# ECC_AGG_TOP_ECC_AGG_TOP register map
Vendor: Texas Instruments
Peripheral module from a debugger description file (folder AM263).
Registers are 8-bit, read-write, reset 0x0 unless marked. A register's access mark holds for its fields unless they carry their own. Offsets are as the file gives them; lines under a group give offsets from that group; [hi:lo] are bit positions; {n}, {i} and the like mark numbered series; 'fields as' and 'values as' point back to an identical list; <NAME> marks a mode.

## ECC_AGG_TOP_ECC_AGG_TOP
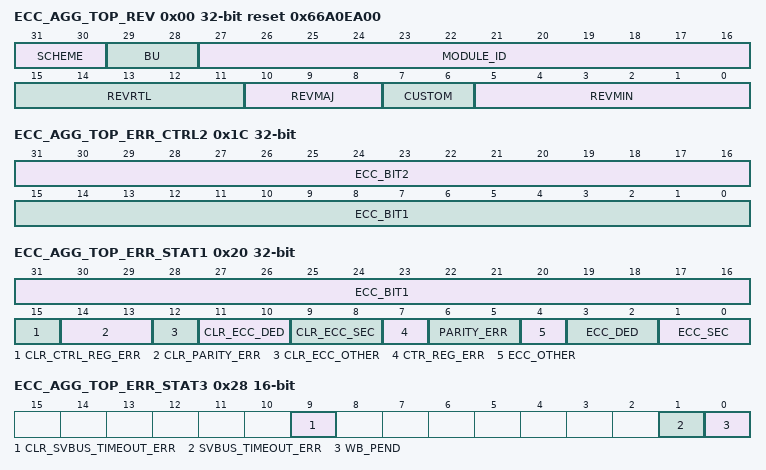
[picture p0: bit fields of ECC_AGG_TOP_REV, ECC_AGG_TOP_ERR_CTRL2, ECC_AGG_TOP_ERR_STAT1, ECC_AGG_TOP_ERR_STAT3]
0x00 ECC_AGG_TOP_REV 32-bit ro reset 0x66A0EA00
  [31:30] SCHEME
  [29:28] BU
  [27:16] MODULE_ID
  [15:11] REVRTL — RTL version
  [10:8] REVMAJ — Major version
  [7:6] CUSTOM — Custom version
  [5:0] REVMIN — Minor version
0x08 ECC_AGG_TOP_VECTOR 24-bit
  [24] RD_SVBUS_DONE — Status to indicate if read on serial VBUS is complete, write of any value will clear this bit.
  [23:16] RD_SVBUS_ADDRESS — Read address
  [15] RD_SVBUS — Write 1 to trigger a read on the serial VBUS
  [10:0] ECC_VECTOR — Value written to select the corresponding ECC RAM for control or status
0x0C ECC_AGG_TOP_STAT 16-bit ro reset 0x9
  [10:0] NUM_RAMS — Indicates the number of RAMS serviced by the ECC aggregator
0x14 ECC_AGG_TOP_CTRL reset 0x187
  [8] CHECK_SVBUS_TIMEOUT — check for svbus timeout errors
  [7] CHECK_PARITY — check for parity errors
  [6] ERROR_ONCE — Force Error only once
  [5] FORCE_N_ROW — Force Error on any RAM read
  [4] FORCE_DED — Force Double Bit Error
  [3] FORCE_SEC — Force Single Bit Error
  [2] ENABLE_RMW
  [1] ECC_CHECK — Enable ECC check
  [0] ECC_ENABLE — Enable ECC
0x18 ECC_AGG_TOP_ERR_CTRL1 32-bit
  [31:0] ECC_ROW — Row address where single or double-bit error needs to be applied. This is ignored if force_n_row is set
0x1C ECC_AGG_TOP_ERR_CTRL2 32-bit
  [31:16] ECC_BIT2 — Data bit that needs to be flipped if double bit error needs to be forced
  [15:0] ECC_BIT1 — Data bit that needs to be flipped when force_sec is set
0x20 ECC_AGG_TOP_ERR_STAT1 32-bit access not given
  [31:16] ECC_BIT1 ro — Data bit that corresponds to the single-bit error
  [15] CLR_CTRL_REG_ERR rw — Clear control reg error Error Status, you must also re write the contorl ergister itself to clear this
  [14:13] CLR_PARITY_ERR — Clear parity Error Status (access RW DECR)
  [12] CLR_ECC_OTHER rw — Clear other Error Status
  [11:10] CLR_ECC_DED — Clear Double Bit Error Status (access RW DECR)
  [9:8] CLR_ECC_SEC — Clear Single Bit Error Status (access RW DECR)
  [7] CTR_REG_ERR rw — control register error pending, Level interrupt
  [6:5] PARITY_ERR rw — Level parity error Error Status
  [4] ECC_OTHER rw — successive single-bit errors have occurred while a writeback is still pending, Level interrupt
  [3:2] ECC_DED — Level Double Bit Error Status (access RW INCR)
  [1:0] ECC_SEC — Level Single Bit Error Status (access RW INCR)
0x24 ECC_AGG_TOP_ERR_STAT2 32-bit ro
  [31:0] ECC_ROW — Row address where the single or double-bit error has occurred
0x28 ECC_AGG_TOP_ERR_STAT3 16-bit access per field
  [9] CLR_SVBUS_TIMEOUT_ERR rw — Clear svbus timeout Error Status
  [1] SVBUS_TIMEOUT_ERR rw — Level svbus timeout error Error Status
  [0] WB_PEND ro — delayed write back pending Status
0x3C ECC_AGG_TOP_SEC_EOI_REG size not given
  [0] EOI_WR — EOI Register
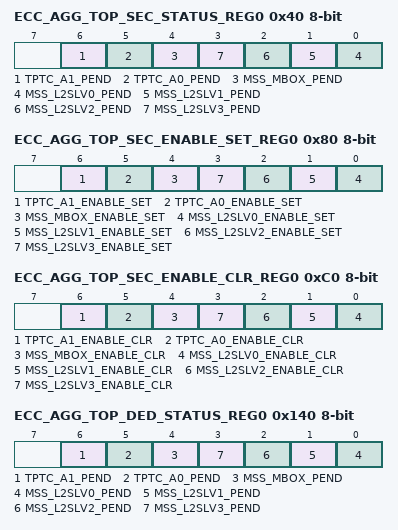
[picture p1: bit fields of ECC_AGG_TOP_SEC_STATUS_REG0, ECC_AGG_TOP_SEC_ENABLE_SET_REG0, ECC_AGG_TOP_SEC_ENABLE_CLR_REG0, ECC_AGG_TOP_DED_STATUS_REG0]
0x40 ECC_AGG_TOP_SEC_STATUS_REG0
  [6] TPTC_A1_PEND — Interrupt Pending Status for tptc_a1_pend
  [5] TPTC_A0_PEND — Interrupt Pending Status for tptc_a0_pend
  [4] MSS_MBOX_PEND — Interrupt Pending Status for mss_mbox_pend
  [n] MSS_L2SLV{n}_PEND (n=0..3) — Interrupt Pending Status for mss_l2slv{n}_pend
0x80 ECC_AGG_TOP_SEC_ENABLE_SET_REG0
  [6] TPTC_A1_ENABLE_SET — Interrupt Enable Set Register for tptc_a1_pend
  [5] TPTC_A0_ENABLE_SET — Interrupt Enable Set Register for tptc_a0_pend
  [4] MSS_MBOX_ENABLE_SET — Interrupt Enable Set Register for mss_mbox_pend
  [n] MSS_L2SLV{n}_ENABLE_SET (n=0..3) — Interrupt Enable Set Register for mss_l2slv{n}_pend
0xC0 ECC_AGG_TOP_SEC_ENABLE_CLR_REG0
  [6] TPTC_A1_ENABLE_CLR — Interrupt Enable Clear Register for tptc_a1_pend
  [5] TPTC_A0_ENABLE_CLR — Interrupt Enable Clear Register for tptc_a0_pend
  [4] MSS_MBOX_ENABLE_CLR — Interrupt Enable Clear Register for mss_mbox_pend
  [n] MSS_L2SLV{n}_ENABLE_CLR (n=0..3) — Interrupt Enable Clear Register for mss_l2slv{n}_pend
0x13C ECC_AGG_TOP_DED_EOI_REG size not given
  [0] EOI_WR — EOI Register
0x140 ECC_AGG_TOP_DED_STATUS_REG0
  fields as ECC_AGG_TOP_SEC_STATUS_REG0
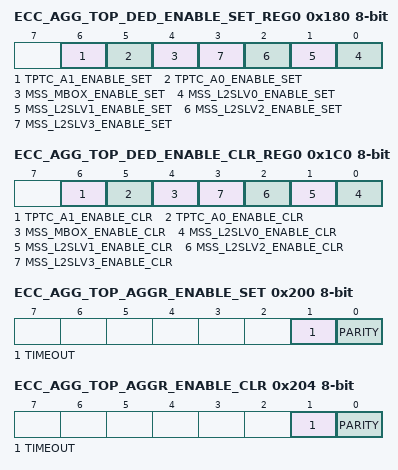
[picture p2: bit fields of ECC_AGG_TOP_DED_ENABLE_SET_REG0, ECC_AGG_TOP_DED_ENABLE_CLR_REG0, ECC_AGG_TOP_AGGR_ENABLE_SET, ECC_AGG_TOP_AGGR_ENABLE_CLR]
0x180 ECC_AGG_TOP_DED_ENABLE_SET_REG0
  fields as ECC_AGG_TOP_SEC_ENABLE_SET_REG0
0x1C0 ECC_AGG_TOP_DED_ENABLE_CLR_REG0
  fields as ECC_AGG_TOP_SEC_ENABLE_CLR_REG0
0x200 ECC_AGG_TOP_AGGR_ENABLE_SET
  [1] TIMEOUT — interrupt enable set for svbus timeout errors
  [0] PARITY — interrupt enable set for parity errors
0x204 ECC_AGG_TOP_AGGR_ENABLE_CLR
  [1] TIMEOUT — interrupt enable clear for svbus timeout errors
  [0] PARITY — interrupt enable clear for parity errors
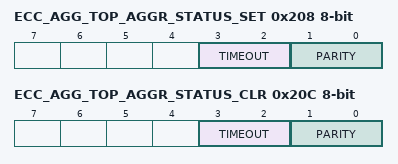
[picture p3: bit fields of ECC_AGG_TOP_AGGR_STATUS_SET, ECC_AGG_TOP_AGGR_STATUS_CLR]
0x208 ECC_AGG_TOP_AGGR_STATUS_SET access not given
  [3:2] TIMEOUT — interrupt status set for svbus timeout errors (access RW INCR)
  [1:0] PARITY — interrupt status set for parity errors (access RW INCR)
0x20C ECC_AGG_TOP_AGGR_STATUS_CLR access not given
  [3:2] TIMEOUT — interrupt status clear for svbus timeout errors (access RW DECR)
  [1:0] PARITY — interrupt status clear for parity errors (access RW DECR)
